# PIC32CX5112MTSH128S1 device description
Architecture: CORTEX-M4; Family: PIC32CXMT; Series: PIC32CXMTSH
Registers are 32-bit, read-write, no defined reset value unless marked. A register's access mark holds for its fields unless they carry their own. Offsets are from the block's base; [hi:lo] are bit positions.

## RTT — Real-time Timer
Instances: RTT 0x40053020
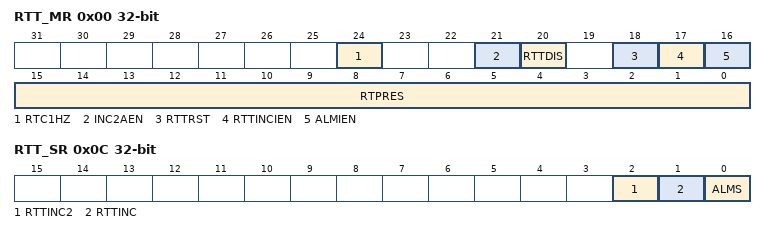
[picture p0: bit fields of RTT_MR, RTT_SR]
0x00 RTT_MR — Mode Register
  [24] RTC1HZ — Real-Time Clock 1Hz Clock Selection
  [21] INC2AEN — RTTINC2 Alarm and Interrupt Enable
  [20] RTTDIS — Real-time Timer Disable
  [18] RTTRST — Real-time Timer Restart
  [17] RTTINCIEN — Real-time Timer Increment Interrupt Enable
  [16] ALMIEN — Alarm Interrupt Enable
  [15:0] RTPRES — Real-time Timer Prescaler Value
0x04 RTT_AR — Alarm Register
  [31:0] ALMV — Alarm Value
0x08 RTT_VR ro — Value Register
  [31:0] CRTV — Current Real-time Value
0x0C RTT_SR ro — Status Register
  [2] RTTINC2 — Predefined Number of Prescaler Roll-overs Status (cleared on read)
  [1] RTTINC — Prescaler Roll-over Status (cleared on read)
  [0] ALMS — Real-time Alarm Status (cleared on read)
0x10 RTT_MODR — Modulo Selection Register
  [2:0] SELINC2 — Selection of the 32-bit Counter Modulo to generate RTTINC2 Flag
    0=NO_RTTINC2 (The RTTINC2 flag never rises); 1=MOD64 (The RTTINC2 flag is set when CRTV modulo 64 equals 0); 2=MOD128 (The RTTINC2 flag is set when CRTV modulo 128 equals 0); 3=MOD256 (The RTTINC2 flag is set when CRTV modulo 256 equals 0); 4=MOD512 (The RTTINC2 flag is set when CRTV modulo 512 equals 0); 5=MOD1024 (The RTTINC2 flag is set when CRTV modulo 1024 equals 0. Example: If RTPRES=32 then RTTINC2 flag rises once per second if the slow clock is 32.768 kHz.); 6=MOD2048 (The RTTINC2 flag is set when CRTV modulo 2048 equals 0); 7=MOD4096 (The RTTINC2 flag is set when CRTV modulo 4096 equals 0)

## SFRBU — Special Function Register Backup
Instances: SFRBU 0x40050600
0x10 SFRBU_XTAL_TRIM — XTAL Oscillator Trimming Register
  [1:0] XTAL_TRIM — 32 kHz Crystal Oscillator Trimming Value
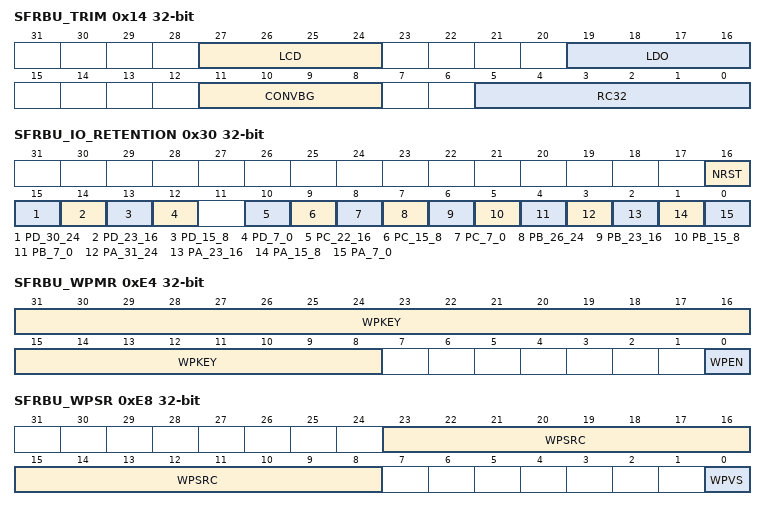
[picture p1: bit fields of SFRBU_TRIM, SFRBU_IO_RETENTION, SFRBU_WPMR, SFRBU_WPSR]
0x14 SFRBU_TRIM ro — Trimming Bits Register
  [27:24] LCD — LDO Internal Bandgap Trimming for LCD Driver
  [19:16] LDO — Power Management IP LDO Trimming Value
  [11:8] CONVBG — Conversion IP Bandgap Trimming Value
  [5:0] RC32 — RC Oscillator Trimming Value
0x20 SFRBU_BOOT — Boot Register
  [0] SOURCE — Source for Booting Sequence
0x30 SFRBU_IO_RETENTION — IO Retention Register
  [16] NRST — Keep Function on NRST
  [15] PD_30_24 — Keep Function on PD24 to PD30
  [14] PD_23_16 — Keep Function on PD16 to PD23
  [13] PD_15_8 — Keep Function on PD8 to PD15
  [12] PD_7_0 — Keep Function on PD0 to PD7
  [10] PC_22_16 — Keep Function on PC16 to PC22
  [9] PC_15_8 — Keep Function on PC8 to PC15
  [8] PC_7_0 — Keep Function on PC0 to PC7
  [7] PB_26_24 — Keep Function on PB24 to PB26
  [6] PB_23_16 — Keep Function on PB216 to PB23
  [5] PB_15_8 — Keep Function on PB8 to PB15
  [4] PB_7_0 — Keep Function on PB0 to PB7
  [3] PA_31_24 — Keep Function on PA24 to PA31
  [2] PA_23_16 — Keep Function on PA16 to PA23
  [1] PA_15_8 — Keep Function on PA8 to PA15
  [0] PA_7_0 — Keep Function on PA0 to PA7
0x40 SFRBU_BODCORE — BOD Core Register
  [0] STATUS — Core Brownout Detector
0x50 SFRBU_PWS_CNTRL — Power Switch Control Register
  [0] UNMASK — Unmask Power Switch Control Signals
0xE4 SFRBU_WPMR — Write Protection Mode Register
  [31:8] WPKEY — Write Protection Key
    0x534652=PASSWD (Writing any other value in this field aborts the write operation of the WPEN bit. Always reads as 0.)
  [0] WPEN — Write Protection Enable
0xE8 SFRBU_WPSR — Write Protection Status Register
  [23:8] WPSRC — Write Protection Source
  [0] WPVS — Write Protection Violation Status
0xF0 SFRBU_SPARE — Spare Register
  [31:0] VALUE — Spare

## SYSCWP — External Interrupt Controller
Instances: SYSCWP 0x400531A0
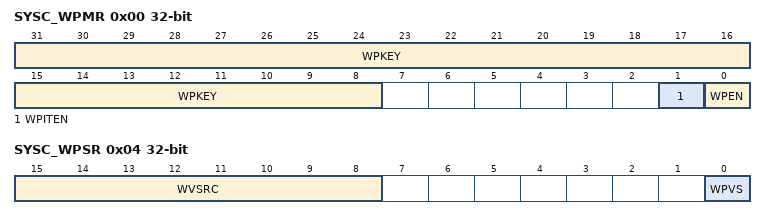
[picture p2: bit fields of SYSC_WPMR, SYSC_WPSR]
0x00 SYSC_WPMR — Write Protection Mode Register
  [31:8] WPKEY — Write Protection Key
    0x535943=PASSWD (Writing any other value in this field aborts the write operation of the WPEN and WPITEN bits. Always reads as 0.)
  [1] WPITEN — Write Protection Interrupt Enable
  [0] WPEN — Write Protection Enable
0x04 SYSC_WPSR ro — Write Protection Status Register
  [15:8] WVSRC — Write Violation Source
  [0] WPVS — Write Protection Register Violation Status
